# RZT2H register map
Vendor: Renesas Electronics Corporation; Series: RZT; File version: 1.00.00
CPU: other r0p0, little endian, MPU, no FPU, VTOR, 4 interrupt priority bits, 624 interrupts
Registers are 32-bit, read-write, reset 0x0 unless marked. A register's access mark holds for its fields unless they carry their own. Offsets are from the block's base; [hi:lo] are bit positions; {n}, {i} and the like mark numbered series; 'fields as' and 'values as' point back to an identical list.

## PCIE_LNK — PCIe Supplimental Settings for LINK MODE
Base 0x80292060
0x00 PCIE_LINKMODE reset 0x100
  [9:8] LINK_MASTER — Channel Configuration
    1=2 lanes x 1 channel; 3=1 lane x 2 channels; other=Others (Setting prohibited)

## XSPI0_MISC — xSPI0 Voltage and Size Registers
Base 0x80293000
Same registers: XSPI1_MISC 0x80293100
0x00 IOVOLCTL — xSPI IO Voltage Control Register
  [0] XSPI_MDV
    0=1.8 V; 1=3.3 V
0x04 CS0ENDAD reset 0x400FFFFF (reset mask 0xEFFFFFFF) — xSPI CS0 End Address Register
  [31:0] CS0_END_ADD — CS0 (slave 0) area end address
0x08 CS1STRAD reset 0x48000000 (reset mask 0xEFFFFFFF) — xSPI CS1 Start Address Register
  [31:0] CS1_STR_ADD — CS1 (slave 1) area start address
0x0C CS1ENDAD reset 0x480FFFFF (reset mask 0xEFFFFFFF) — xSPI CS1 End Address Register
  [31:0] CS1_END_ADD — CS1 (slave 0) area end address

## MD_NS — Operating Mode for Non-safety Area
Base 0x80294100
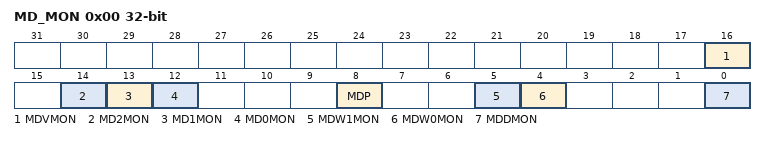
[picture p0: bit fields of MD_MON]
0x00 MD_MON ro (reset mask 0xFFFE8ECE) — Operating Mode Monitor Register
  [16] MDVMON — MDV status flag
  [14] MD2MON — MD2 pin status flag
  [13] MD1MON — MD1 pin status flag
  [12] MD0MON — MD0 pin status flag
  [8] MDP — Package type
    0=RZ/T2H 729pin FCBGA; 1=RZ/N2H 576pin FCBGA
  [5] MDW1MON — MDW1 status flag
  [4] MDW0MON — MDW0 status flag
  [0] MDDMON — MDD status flag

## RWP_NS — Register Write Protection for Non-safety Area
Base 0x80294200
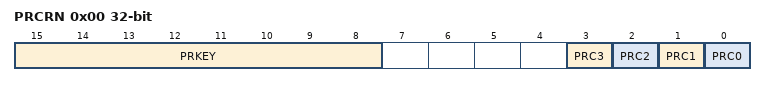
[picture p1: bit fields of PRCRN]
0x00 PRCRN — Non_Safety Area Protect Register
  [15:8] PRKEY wo — PRC Key Code
  [n] PRC{n} (n=0..3) — Protect {n}
    0=Write disabled; 1=Write enabled

## ELC — Event Link Controller
Base 0x802A0698
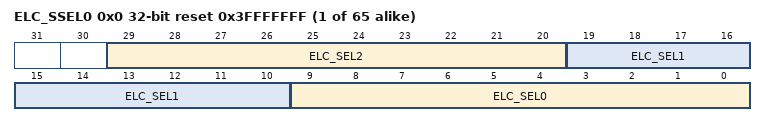
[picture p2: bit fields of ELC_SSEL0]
{0x0+4i} ELC_SSEL{i} (i=0..64) reset 0x3FFFFFFF — ELC Event Source Select Register {i}
  [29:20] ELC_SEL2 — Set the number for ELC event source to be linked to the ELC destination.
  [19:10] ELC_SEL1 — Set the number for ELC event source to be linked to the ELC destination.
  [9:0] ELC_SEL0 — Set the number for ELC event source to be linked to the ELC destination.

## DMA — DMAC Configuration
Base 0x802A07D0
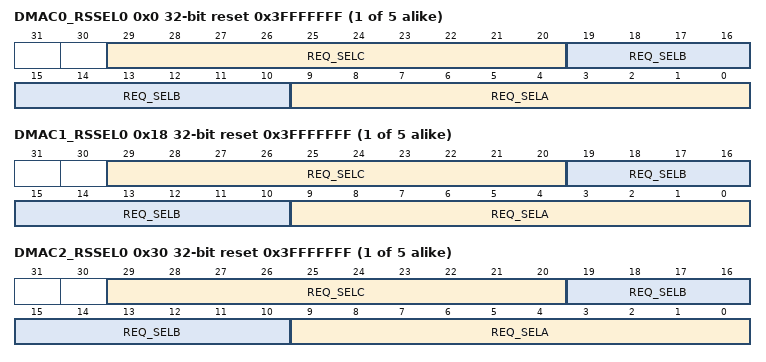
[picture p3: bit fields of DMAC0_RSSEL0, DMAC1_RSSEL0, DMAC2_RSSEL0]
{0x0+4i} DMAC0_RSSEL{i} (i=0..4) reset 0x3FFFFFFF — DMAC Unit 0 Resource Select Register {i}
  [29:20] REQ_SELC — DMA Resource Select for Channel n + 2
  [19:10] REQ_SELB — DMA Resource Select for Channel n + 1
  [9:0] REQ_SELA — DMA Resource Select for Channel n
{0x14+0x18*i} DMAC{i}_RSSEL5 reset 0x3FF (i=0..2) — DMAC Unit {i} Resource Select Register 5
  [9:0] REQ_SELA — DMA Resource Select for Channel n
{0x18+4i} DMAC1_RSSEL{i} (i=0..4) reset 0x3FFFFFFF — DMAC Unit 1 Resource Select Register {i}
  fields as DMAC0_RSSEL0
{0x30+4i} DMAC2_RSSEL{i} (i=0..4) reset 0x3FFFFFFF — DMAC Unit 2 Resource Select Register {i}
  fields as DMAC0_RSSEL0

## OTP — One-Time Programmable Memory
Base 0x810C0000
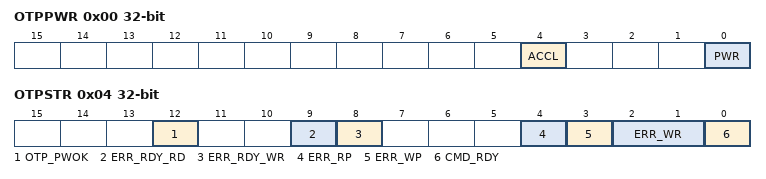
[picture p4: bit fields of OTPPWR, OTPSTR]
0x00 OTPPWR — OTP Power Control Register
  [4] ACCL — Selects OTP access I/F
    0=Not selected; 1=Selected
  [0] PWR — OTP power on/off setting
    0=Power off; 1=Power on
0x04 OTPSTR — OTP Access Status Register
  [12] OTP_PWOK ro — Indicates power on/off status of OTP Memory
    0=Power Off; 1=Power On
  [9] ERR_RDY_RD — OTP read command ready error
  [8] ERR_RDY_WR — OTP write command ready error
  [4] ERR_RP ro — Read protection error
  [3] ERR_WP ro — Write protection error
  [2:1] ERR_WR ro — OTP write status
    0=PASS; 1=Fail due to overwrite to the area where WORDLOCK bit is set to 1; 2=1 bit write error
  [0] CMD_RDY ro — Indicates whether OTP controller is ready to receive command or not.
    0=Not ready; 1=Ready
0x08 OTPSTAWR — OTP Write Command Register
  [0] STAWR — OTP write start
0x0C OTPADRWR — OTP Write Address Register
  [9:0] ADRWR — OTP write address
0x10 OTPDATAWR — OTP Write Data Register
  [31:0] DATAWR — OTP write data
0x14 OTPADRRD — OTP Read Address Register
  [9:0] ADRRD — OTP read address
0x18 OTPDATARD ro — OTP Read Data Register
  [31:0] DATARD — OTP read data
